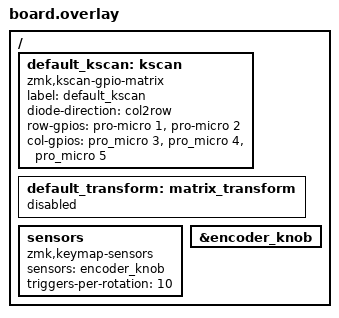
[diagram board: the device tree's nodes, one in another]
#include <dt-bindings/zmk/matrix_transform.h>

/ {
    default_kscan: kscan {
        compatible = "zmk,kscan-gpio-matrix";
        label = "default_kscan";
        diode-direction = "col2row";

        row-gpios = <&pro-micro 1 (GPIO_ACTIVE_HIGH | GPIO_PULL_DOWN)>,
                    <&pro-micro 2 (GPIO_ACTIVE_HIGH | GPIO_PULL_DOWN)>;
        
        col-gpios = <&pro_micro 3 GPIO_ACTIVE_HIGH>,
                    <&pro_micro 4 GPIO_ACTIVE_HIGH>,
                    <&pro_micro 5 GPIO_ACTIVE_HIGH>;
    };

    default_transform: matrix_transform {             /*allows for custom shape in matrix,*|
        compatible = "zmk,matrix-transform";          /*expects basic matrix without this*|
        rows = <2>;
        columns = <3>;

        map = <
            RC(0,0) RC(0,1) RC(0,2)
            RC(1,0) RC(1,1) RC(1,2)
        >;
    };


    encoder_knob: encoder_knob {
        compatible = "alps,ec11";
        a-gpios = <PIN_A (GPIO_ACTIVE_HIGH | GPIO_PULL_UP)>;          
        b-gpios = <PIN_B (GPIO_ACTIVE_HIGH | GPIO_PULL_UP)>;
        steps = <80>;                                /*changes depending on encoder*/
        status = "disabled";
    };

    sensors: sensors {
        compatible = "zmk,keymap-sensors";
        sensors = <&encoder_knob>;
        triggers-per-rotation = <10>;            /*# of times behavior is triggered in 1 full rotation*/
    };

    &encoder_knob {
        status = "okay";
    };
};
